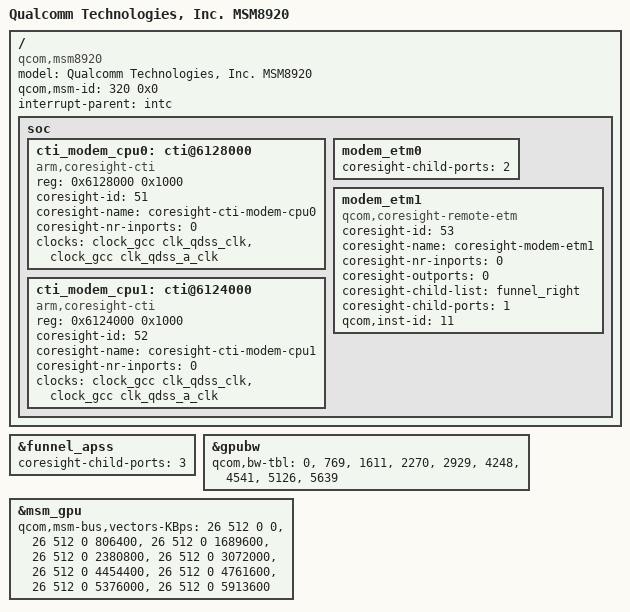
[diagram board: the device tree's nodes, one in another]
/*
 * Copyright (c) 2016, The Linux Foundation. All rights reserved.
 *
 * This program is free software; you can redistribute it and/or modify
 * it under the terms of the GNU General Public License version 2 and
 * only version 2 as published by the Free Software Foundation.
 *
 * This program is distributed in the hope that it will be useful,
 * but WITHOUT ANY WARRANTY; without even the implied warranty of
 * MERCHANTABILITY or FITNESS FOR A PARTICULAR PURPOSE.  See the
 * GNU General Public License for more details.
 */

#include "skeleton64.dtsi"
#include "msm8917.dtsi"

/ {
	model = "Qualcomm Technologies, Inc. MSM8920";
	compatible = "qcom,msm8920";
	qcom,msm-id = <320 0x0>;
	interrupt-parent = <&intc>;

	soc: soc { };
};

&funnel_apss {
	coresight-child-ports = <3>;
};

&soc {
	/delete-node/ cti@6124000;
	cti_modem_cpu0: cti@6128000 {
		compatible = "arm,coresight-cti";
		reg = <0x6128000 0x1000>;
		reg-names = "cti-base";

		coresight-id = <51>;
		coresight-name = "coresight-cti-modem-cpu0";
		coresight-nr-inports = <0>;

		clocks = <&clock_gcc clk_qdss_clk>,
			 <&clock_gcc clk_qdss_a_clk>;
		clock-names = "core_clk", "core_a_clk";
	};

	/* MSS_SCL */
	modem_etm0 {
		coresight-child-ports = <2>;
	};

	cti_modem_cpu1: cti@6124000 {
		compatible = "arm,coresight-cti";
		reg = <0x6124000 0x1000>;
		reg-names = "cti-base";

		coresight-id = <52>;
		coresight-name = "coresight-cti-modem-cpu1";
		coresight-nr-inports = <0>;

		clocks = <&clock_gcc clk_qdss_clk>,
			 <&clock_gcc clk_qdss_a_clk>;
		clock-names = "core_clk", "core_a_clk";
	};

	/* MSS_VEC */
	modem_etm1 {
		compatible = "qcom,coresight-remote-etm";

		coresight-id = <53>;
		coresight-name = "coresight-modem-etm1";
		coresight-nr-inports = <0>;
		coresight-outports = <0>;
		coresight-child-list = <&funnel_right>;
		coresight-child-ports = <1>;

		qcom,inst-id = <11>;
	};
};

&funnel_apss {
	coresight-child-ports = <3>;
};

&soc {
	/delete-node/ cti@6124000;
	cti_modem_cpu0: cti@6128000 {
		compatible = "arm,coresight-cti";
		reg = <0x6128000 0x1000>;
		reg-names = "cti-base";

		coresight-id = <51>;
		coresight-name = "coresight-cti-modem-cpu0";
		coresight-nr-inports = <0>;

		clocks = <&clock_gcc clk_qdss_clk>,
			 <&clock_gcc clk_qdss_a_clk>;
		clock-names = "core_clk", "core_a_clk";
	};

	/* MSS_SCL */
	modem_etm0 {
		coresight-child-ports = <2>;
	};

	cti_modem_cpu1: cti@6124000 {
		compatible = "arm,coresight-cti";
		reg = <0x6124000 0x1000>;
		reg-names = "cti-base";

		coresight-id = <52>;
		coresight-name = "coresight-cti-modem-cpu1";
		coresight-nr-inports = <0>;

		clocks = <&clock_gcc clk_qdss_clk>,
			 <&clock_gcc clk_qdss_a_clk>;
		clock-names = "core_clk", "core_a_clk";
	};

	/* MSS_VEC */
	modem_etm1 {
		compatible = "qcom,coresight-remote-etm";

		coresight-id = <53>;
		coresight-name = "coresight-modem-etm1";
		coresight-nr-inports = <0>;
		coresight-outports = <0>;
		coresight-child-list = <&funnel_right>;
		coresight-child-ports = <1>;

		qcom,inst-id = <11>;
	};
};

/* gpubw overrides */
&gpubw {
	/delete-property/ qcom,bw-tbl;
	qcom,bw-tbl =
			< 0 >,    /* Off */
			< 769 >, /* 1. DDR:100.80 MHz BIMC: 201.60 MHz */
			< 1611>, /* 2. DDR:211.20 MHz BIMC: 422.40 MHz */
			< 2270>, /* 3. DDR:297.60 MHz BIMC: 595.20 MHz */
			< 2929>, /* 4. DDR:384.00 MHz BIMC: 768.00 MHz */
			< 4248>, /* 5. DDR:556.80 MHz BIMC: 1113.60 MHz */
			< 4541>, /* 6. DDR:595.20 MHz BIMC: 1190.40 MHz */
			< 5126>, /* 7. DDR:672.00 MHz BIMC: 1344.00 MHz */
			< 5639>; /* 8. DDR:739.20 MHz BIMC: 1478.40 MHz */
};

/* GPU overrides */
&msm_gpu {

	/delete-property/ qcom,msm-bus,vectors-KBps;
	qcom,msm-bus,vectors-KBps =
				<26 512 0 0>,	    /*    off        */
				<26 512 0   806400>, /* 1. 100.80 MHz */
				<26 512 0  1689600>, /* 2. 211.20 MHz */
				<26 512 0  2380800>, /* 3. 297.60 MHz */
				<26 512 0  3072000>, /* 4. 384.00 MHz */
				<26 512 0  4454400>, /* 5. 556.80 MHz */
				<26 512 0  4761600>, /* 6. 595.20 MHz */
				<26 512 0  5376000>, /* 7. 672.00 MHz */
				<26 512 0  5913600>; /* 8. 739.20 MHz */
};
